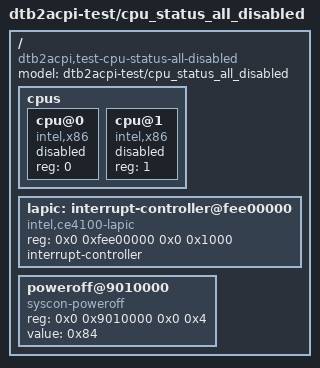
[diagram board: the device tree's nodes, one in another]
/dts-v1/;

/* Every cpu has a non-`okay` `status`. In particular cpu@0 — the
 * conventional BSP — is disabled, so count surfaces
 * `BootCpuNotEnabled` (a self-contradictory MADT for the BSP-as-
 * itself would result otherwise).
 */

/ {
	#address-cells = <2>;
	#size-cells = <2>;
	model = "dtb2acpi-test/cpu_status_all_disabled";
	compatible = "dtb2acpi,test-cpu-status-all-disabled";

	cpus {
		#address-cells = <1>;
		#size-cells = <0>;

		cpu@0 {
			device_type = "cpu";
			reg = <0>;
			compatible = "intel,x86";
			status = "disabled";
		};

		cpu@1 {
			device_type = "cpu";
			reg = <1>;
			compatible = "intel,x86";
			status = "fail";
		};
	};

		lapic: interrupt-controller@fee00000 {
		compatible = "intel,ce4100-lapic";
		reg = <0x0 0xfee00000 0x0 0x1000>;
		interrupt-controller;
		#interrupt-cells = <2>;
	};
		poweroff@9010000 {
		compatible = "syscon-poweroff";
		reg = <0x0 0x9010000 0x0 0x4>;
		value = <0x84>;
	};
};
